AUTOSAR XML (schema 4-2-2)
standard types defined: uint8
package /Acme/Chassis/DataTypes
  5 x impl type, all with category=VALUE, base-type=uint8:
    Counter
    Level
    Mode: compu {0=OFF, 1=ON}
    Gear
    Speed
  application record data type Point
    application record element x: type=Counter
    application record element y: type=Counter
  application array data type Triple
    element TripleElement: type=Counter, max-number-of-elements=3
  application array data type PointPair
    element PointPairElement: type=Point, max-number-of-elements=2
package /Acme/Chassis/ApplicationTypes
  app type Counter: category=VALUE
  app type Gear: category=VALUE, compu {0=PARK, 1=DRIVE}
  app type Speed: category=VALUE, unit=km/h
package /Acme/Chassis/Units
  unit KilometrePerHour: display-name=km/h
package /Acme/Chassis/DataTypeMappingSets
  data type mapping set Acme_Chassis_DataTypeMapping
    data-type-maps:
      application-data-type=Counter, implementation-data-type=Counter
      application-data-type=Gear, implementation-data-type=Gear
      application-data-type=Speed, implementation-data-type=Speed
package /Acme/Chassis/Constants
  8 x constant specification:
    SR_IScalars_counter_Init: value-spec=0xff
    SR_IScalars_level_Init: value-spec=7
    SR_IScalars_gear_Init: value-spec=DRIVE
    SR_IScalars_speed_Init: value-spec=30 km/h
    SR_IScalars_mode_Init: value-spec=ON
    SR_IComposites_triple_Init: value-spec=[0, 1, 0x10]
    SR_IComposites_point_Init: value-spec={short-label=point_Init, fields=[5, 0x0a]}
    SR_IComposites_pairs_Init: value-spec=[fields=[1, 2], fields=[3, 4]]
package /Acme/Chassis/Interfaces
  sender receiver interface IScalars
    6 x data:
      counter: type=Counter, init-value=constant-reference=SR_IScalars_counter_Init
      level: type=Level, init-value=constant-reference=SR_IScalars_level_Init
      gear: type=Gear, init-value=constant-reference=SR_IScalars_gear_Init
      speed: type=Speed, init-value=constant-reference=SR_IScalars_speed_Init
      mode: type=Mode, init-value=constant-reference=SR_IScalars_mode_Init
      uninitialized: type=Counter
  sender receiver interface IComposites
    data triple: type=Triple, init-value=constant-reference=SR_IComposites_triple_Init
    data point: type=Point, init-value=constant-reference=SR_IComposites_point_Init
    data pairs: type=PointPair, init-value=constant-reference=SR_IComposites_pairs_Init
package /Acme/Chassis/Components
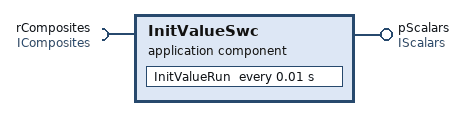
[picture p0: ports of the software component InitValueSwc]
  application sw component type InitValueSwc
    provide port pScalars: nonqueued-sender-com-spec{data-element=counter, init-value=constant-reference=SR_IScalars_counter_Init}, provided-interface=IScalars
    require port rComposites: nonqueued-receiver-com-spec{data-element=point, init-value=constant-reference=SR_IComposites_point_Init}, required-interface=IComposites
    behavior InitValueSwc_InternalBehavior: data-type-mapping=Acme_Chassis_DataTypeMapping, handle-termination-and-restart=NO-SUPPORT
      timing event TMT_InitValueRun: start-on-event=InitValueRun, period=0.01
      runnable InitValueRun: minimum-start-interval=0.01
